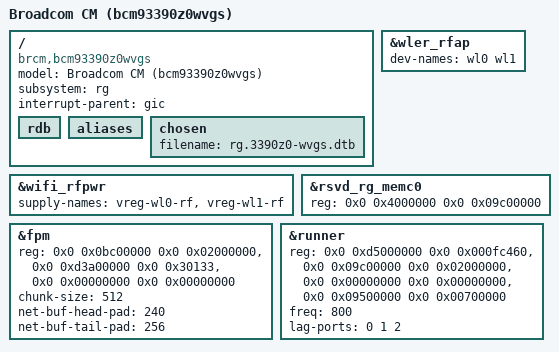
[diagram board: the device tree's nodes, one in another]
/dts-v1/;

/ {
	model = "Broadcom CM (bcm93390z0wvgs)";
	compatible = "brcm,bcm93390z0wvgs",
		     "brcm,bcm3390z0",
		     "brcm,bcm3390",
		     "brcm,brcmcm", "brcm,brcmstb";
	subsystem = "rg";
	#address-cells = <0x2>;
	#size-cells = <0x2>;
	interrupt-parent = <&gic>;
};

/include/ "rg.3390b0-bolt.dtsi"
/include/ "rg.3390-base.dtsi"
/include/ "rg.3390-wifi.dtsi"
/include/ "rg.3390z0-bolt.dtsi"

/********************************************************************
 * any nodes that appear below are platform specific additions and
 * replacements.
 * The dtc will add or replace any properties in the nodes
 * below to the same nodes that appear in include files above.
 * If the property does not exist in the node above it will be added.
 * If the property does exist it will replace it.
 ********************************************************************/
&wler_rfap {
	dev-names = "wl0 wl1";
};

&wifi_rfpwr {
	supply-names = "vreg-wl0-rf", "vreg-wl1-rf";
	/delete-property/vreg-wl2-rf-supply;
};

/ {
	/delete-node/vreg-wl2;
	/delete-node/vreg-wl2-rf;

	rdb {
		/delete-node/sdhci@f04a0100;
		/delete-node/sdhci@f04a0300;
	};

	aliases {
		/delete-property/sdhci0;
		/delete-property/sdhci1;
	};

	chosen {
		filename = "rg.3390z0-wvgs.dtb";
	};
};

&rsvd_rg_memc0 {
	reg = <0x0 0x4000000 0x0 0x09c00000>;
};

&fpm {
	reg = <0x0 0x0bc00000 0x0 0x02000000>,	/* Free Pool 0			*/
	      <0x0 0xd3a00000 0x0 0x30133>,	/* Registers			*/
	      <0x0 0x00000000 0x0 0x00000000>;	/* Free Pool 1			*/
	chunk-size = <512>;
	net-buf-head-pad = <240>;
	net-buf-tail-pad = <256>;
};

&runner {
	reg = <0x0 0xd5000000 0x0 0x000fc460>,	/* Registers			*/
	      <0x0 0x09c00000 0x0 0x02000000>,	/* Runner Extra Memory 0	*/
	      <0x0 0x00000000 0x0 0x00000000>,	/* Runner Extra Memory 1	*/
	      <0x0 0x09500000 0x0 0x00700000>;	/* Runner NAT Cache		*/
	freq = <800>;				/* MHz				*/
	lag-ports = < 0 1 2 >;
};
